# MB9BF32xT register map
File version: 1.2
CPU: 
Registers are 8-bit, read-write, reset 0x0 unless marked. A register's access mark holds for its fields unless they carry their own. Offsets are from the block's base; [hi:lo] are bit positions; {n}, {i} and the like mark numbered series.

## DAC — D/A Converter
Base 0x40028000
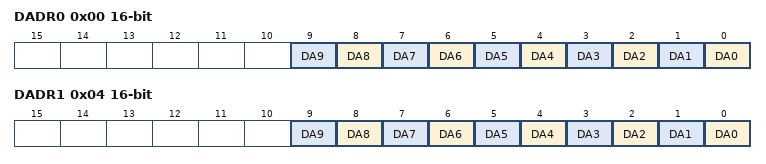
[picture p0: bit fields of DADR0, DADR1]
0x00 DADR0 16-bit reset not defined — D/A Data Register
  [n] DA{n} (n=0..9) — Bit{n} of DADR0
0x02 DACR0 reset not defined — D/A Control Register
  [0] DAE — D/A converter operation enable bit
0x04 DADR1 16-bit reset not defined — D/A Data Register
  [n] DA{n} (n=0..9) — Bit{n} of DADR1
0x06 DACR1 reset not defined — D/A Control Register
  [0] DAE — D/A converter operation enable bit

## EXTI — External Interrupt and NMI Control
Base 0x40030000
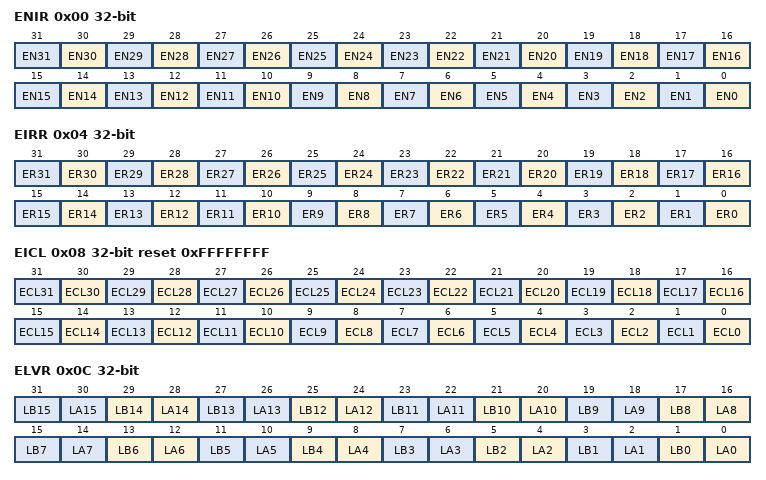
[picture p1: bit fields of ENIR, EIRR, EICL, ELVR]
0x00 ENIR 32-bit — Enable Interrupt Request Register
  [n] EN{n} (n=0..31) — Bit{n} of ENIR
0x04 EIRR 32-bit ro reset not defined — External Interrupt Request Register
  [n] ER{n} (n=0..31) — Bit{n} of EIRR
0x08 EICL 32-bit reset 0xFFFFFFFF — External Interrupt Clear Register
  [n] ECL{n} (n=0..31) — Bit{n} of EICL
0x0C ELVR 32-bit — External Interrupt Level Register
  [2n+1] LB{n} (n=0..15) — Bit{2n+1} of ELVR
  [2n] LA{n} (n=0..15) — Bit{2n} of ELVR
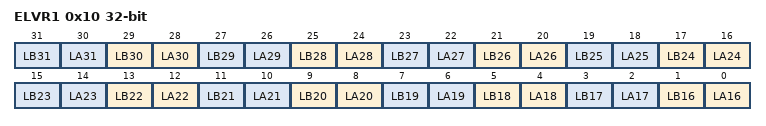
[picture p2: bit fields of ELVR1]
0x10 ELVR1 32-bit — External Interrupt Level Register 1
  [2n-31] LB{n} (n=16..31) — Bit{2n-31} of ELVR1
  [2n-32] LA{n} (n=16..31) — Bit{2n-32} of ELVR1
0x14 NMIRR ro — Non Maskable Interrupt Request Register
  [0] NR — NMI interrupt request detection bit
0x18 NMICL reset 0x1 — Non Maskable Interrupt Clear Register
  [0] NCL — NMI interrupt cause clear bit

## HDMICEC0 — HDMI-CEC ch.0
Base 0x40034000
Same registers: HDMICEC1 0x40034100
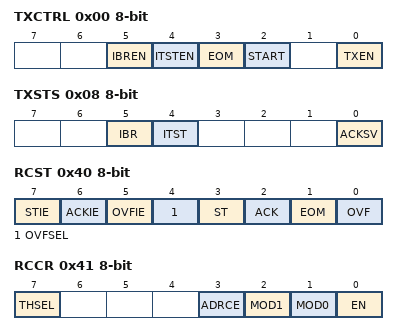
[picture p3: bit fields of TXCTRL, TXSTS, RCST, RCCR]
0x00 TXCTRL — Transmission Control Register
  [5] IBREN — Bus error detection interrupt enable bit
  [4] ITSTEN — transmission status interrupt enable bit
  [3] EOM — EOM setting bit
  [2] START — START setting bit
  [0] TXEN — Transmission operation enable bit
0x04 TXDATA — Transmission Data Register
  [7:0] TXDATA — Transmission Data
0x08 TXSTS — Transmission Status Register
  [5] IBR — Bus error detection interrupt request bit
  [4] ITST — Transmission status interrupt request bit
  [0] ACKSV — ACK cycle value bit
0x0C SFREE — Signal Free Time Setting Register
  [3:0] SFREE — Signal free time setting bits
0x40 RCST — Reception Interrupt Control Register
  [7] STIE — Start bit interrupt enable bit
  [6] ACKIE — ACK interrupt enable bit
  [5] OVFIE — Counter overflow interrupt enable bit
  [4] OVFSEL — Counter overflow detection condition setting bit
  [3] ST — Start bit detection bit
  [2] ACK — ACK: ACK detection bit
  [1] EOM — EOM detection bit
  [0] OVF — Counter overflow detection bit
0x41 RCCR — Reception Control Register
  [7] THSEL — Threshold selection bit
  [3] ADRCE — Address comparison enable bit
  [2] MOD1 — Operation mode setting bits
  [1] MOD0 — Operation mode setting bits
  [0] EN — Operation enable bit
0x44 RCDAHW — "H" Width Setting Register A
  [7:0] RCDAHW — "H" Width Setting A
0x45 RCSHW — Start Bit "H" Width Setting Register
  [7:0] RCSHW — Start Bit "H" Width Setting
0x49 RCDBHW — "H" Width Setting Register B
  [7:0] RCDBHW — "H" Width Setting B
0x4C RCADR2 — Device Address Setting Register 2
  [4:0] RCADR2 — Device Address 2
0x4D RCADR1 — Device Address Setting Register 1
  [4:0] RCADR1 — Device Address 1
0x50 RCDTHL ro — Data Save Register (High-Low)
0x51 RCDTHH ro — Data Save Register (High-High)
0x54 RCDTLL ro — Data Save Register (Low-Low)
0x55 RCDTLH ro — Data Save Register (Low-High)
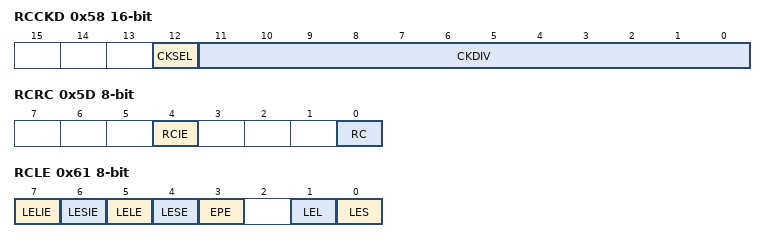
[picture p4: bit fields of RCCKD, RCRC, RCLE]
0x58 RCCKD 16-bit — Clock Division Setting Register
  [12] CKSEL — Operating clock selection bit
  [11:0] CKDIV — Operating clock division setting bits
0x5C RCRHW — Repeat Code "H" Width Setting Register
  [7:0] RCRHW — "Repeat code "H" width setting bits"
0x5D RCRC — Repeat Code Interrupt Control Register
  [4] RCIE — Repeat Code Interrupt enable bit
  [0] RC — Repeat code detection flag bit
0x61 RCLE — Data Bit Width Violation Control Register
  [7] LELIE — Maximum data bit width violation interrupt enable bit
  [6] LESIE — Minimum data bit width violation interrupt enable bit
  [5] LELE — Maximum data bit width violation detection enable bit
  [4] LESE — Minimum data bit width violation detection enable bit
  [3] EPE — Error pulse output enable bit
  [1] LEL — Maximum data bit width violation detection flag bit
  [0] LES — Minimum data bit width violation detection flag bit
0x64 RCLESW — Minimum Data Bit Width Setting Register
  [7:0] RCLESW — Minimum data bit width setting bits
0x65 RCLELW — Maximum Data Bit Width Setting Register
  [7:0] RCLELW — Maximum data bit width setting bits
